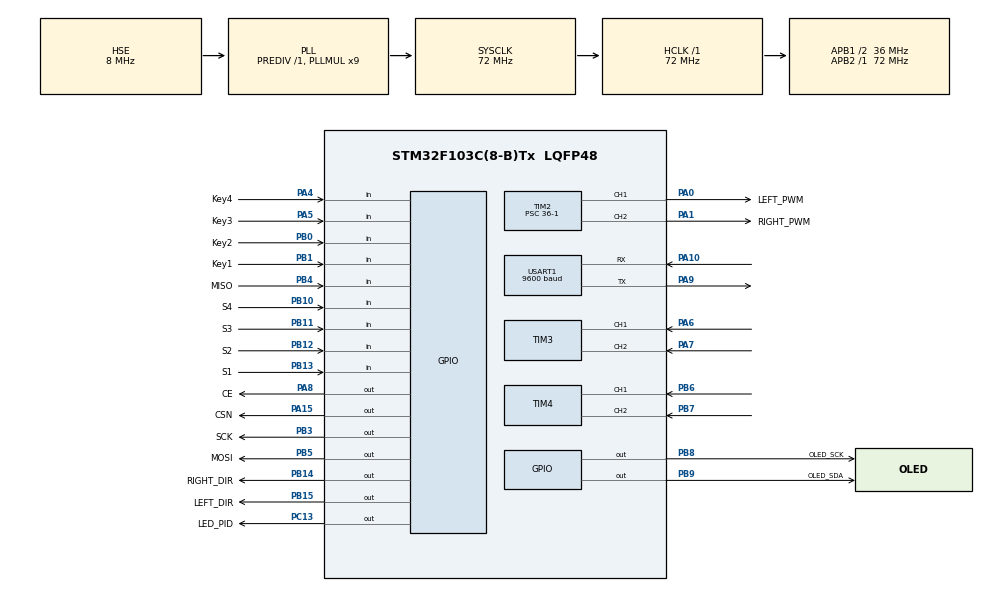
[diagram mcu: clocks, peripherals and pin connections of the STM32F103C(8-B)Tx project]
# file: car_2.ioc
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Dma.Request0=USART1_RX
Dma.USART1_RX.0.Direction=DMA_PERIPH_TO_MEMORY
Dma.USART1_RX.0.Instance=DMA1_Channel5
Dma.USART1_RX.0.MemDataAlignment=DMA_MDATAALIGN_BYTE
Dma.USART1_RX.0.MemInc=DMA_MINC_ENABLE
Dma.USART1_RX.0.Mode=DMA_NORMAL
Dma.USART1_RX.0.PeriphDataAlignment=DMA_PDATAALIGN_BYTE
Dma.USART1_RX.0.PeriphInc=DMA_PINC_DISABLE
Dma.USART1_RX.0.Priority=DMA_PRIORITY_LOW
Mcu.Family=STM32F1
Mcu.Name=STM32F103C(8-B)Tx
Mcu.Package=LQFP48
NVIC.DMA1_Channel5_IRQn=true\:0\:0\:false\:false\:true\:false\:true\:true
NVIC.PriorityGroup=NVIC_PRIORITYGROUP_4
NVIC.USART1_IRQn=true\:0\:0\:false\:false\:true\:true\:true\:true
PA0-WKUP.GPIO_Label=LEFT_PWM
PA0-WKUP.Signal=S_TIM2_CH1_ETR
PA1.GPIO_Label=RIGHT_PWM
PA1.Signal=S_TIM2_CH2
PA10.Mode=Asynchronous
PA10.Signal=USART1_RX
PA13.Mode=Serial_Wire
PA13.Signal=SYS_JTMS-SWDIO
PA14.Mode=Serial_Wire
PA14.Signal=SYS_JTCK-SWCLK
PA15.GPIO_Label=CSN
PA15.Signal=GPIO_Output
PA4.GPIO_Label=Key4
PA4.GPIO_PuPd=GPIO_PULLUP
PA4.Signal=GPIO_Input
PA5.GPIO_Label=Key3
PA5.GPIO_PuPd=GPIO_PULLUP
PA5.Signal=GPIO_Input
PA6.Signal=S_TIM3_CH1
PA7.Signal=S_TIM3_CH2
PA8.GPIO_Label=CE
PA8.Signal=GPIO_Output
PA9.Mode=Asynchronous
PA9.Signal=USART1_TX
PB0.GPIO_Label=Key2
PB0.GPIO_PuPd=GPIO_PULLUP
PB0.Signal=GPIO_Input
PB1.GPIO_Label=Key1
PB1.GPIO_PuPd=GPIO_PULLUP
PB1.Signal=GPIO_Input
PB10.GPIO_Label=S4
PB10.Signal=GPIO_Input
PB11.GPIO_Label=S3
PB11.Signal=GPIO_Input
PB12.GPIO_Label=S2
PB12.Signal=GPIO_Input
PB13.GPIO_Label=S1
PB13.Signal=GPIO_Input
PB14.GPIO_Label=RIGHT_DIR
PB14.Signal=GPIO_Output
PB15.GPIO_Label=LEFT_DIR
PB15.Signal=GPIO_Output
PB3.GPIO_Label=SCK
PB3.Signal=GPIO_Output
PB4.GPIO_Label=MISO
PB4.GPIO_PuPd=GPIO_PULLUP
PB4.Signal=GPIO_Input
PB5.GPIO_Label=MOSI
PB5.Signal=GPIO_Output
PB6.Signal=S_TIM4_CH1
PB7.Signal=S_TIM4_CH2
PB8.GPIO_Label=OLED_SCK
PB8.Signal=GPIO_Output
PB9.GPIO_Label=OLED_SDA
PB9.Signal=GPIO_Output
PC13-TAMPER-RTC.GPIO_Label=LED_PID
PC13-TAMPER-RTC.PinState=GPIO_PIN_SET
PC13-TAMPER-RTC.Signal=GPIO_Output
PD0-OSC_IN.Mode=HSE-External-Oscillator
PD0-OSC_IN.Signal=RCC_OSC_IN
PD1-OSC_OUT.Mode=HSE-External-Oscillator
PD1-OSC_OUT.Signal=RCC_OSC_OUT
ProjectManager.HeapSize=0x200
ProjectManager.StackSize=0x400
ProjectManager.TargetToolchain=MDK-ARM V5.32
RCC.AHBFreq_Value=72000000
RCC.APB1CLKDivider=RCC_HCLK_DIV2
RCC.APB1Freq_Value=36000000
RCC.APB1TimFreq_Value=72000000
RCC.APB2Freq_Value=72000000
RCC.APB2TimFreq_Value=72000000
RCC.HCLKFreq_Value=72000000
RCC.PLLMUL=RCC_PLL_MUL9
RCC.PLLSourceVirtual=RCC_PLLSOURCE_HSE
RCC.RTCClockSelection=RCC_RTCCLKSOURCE_LSE
RCC.SYSCLKFreq_VALUE=72000000
RCC.SYSCLKSource=RCC_SYSCLKSOURCE_PLLCLK
RCC.USBFreq_Value=72000000
SH.S_TIM2_CH1_ETR.0=TIM2_CH1,PWM Generation1 CH1
SH.S_TIM2_CH2.0=TIM2_CH2,PWM Generation2 CH2
SH.S_TIM3_CH1.0=TIM3_CH1,Encoder_Interface
SH.S_TIM3_CH2.0=TIM3_CH2,Encoder_Interface
SH.S_TIM4_CH1.0=TIM4_CH1,Encoder_Interface
SH.S_TIM4_CH2.0=TIM4_CH2,Encoder_Interface
TIM1.Period=100-1
TIM1.Prescaler=720-1
TIM2.Channel-PWM\ Generation1\ CH1=TIM_CHANNEL_1
TIM2.Channel-PWM\ Generation2\ CH2=TIM_CHANNEL_2
TIM2.Period=5000-1
TIM2.Prescaler=36-1
TIM3.EncoderMode=TIM_ENCODERMODE_TI12
TIM3.IC1Filter=15
TIM3.IC1Polarity=TIM_ICPOLARITY_FALLING
TIM4.EncoderMode=TIM_ENCODERMODE_TI12
TIM4.IC1Polarity=TIM_ICPOLARITY_FALLING
TIM4.IC2Polarity=TIM_ICPOLARITY_FALLING
USART1.BaudRate=9600
USART1.VirtualMode=VM_ASYNC
VP_TIM1_VS_ClockSourceINT.Mode=Internal
board=custom

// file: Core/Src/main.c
/* USER CODE BEGIN Header */
/**
  ******************************************************************************
  * @file           : main.c
  * @brief          : Main program body
  ******************************************************************************
  * @attention
  *
  * Copyright (c) 2026 STMicroelectronics.
  * All rights reserved.
  *
  * This software is licensed under terms that can be found in the LICENSE file
  * in the root directory of this software component.
  * If no LICENSE file comes with this software, it is provided AS-IS.
  *
  ******************************************************************************
  */
/* USER CODE END Header */
#include "main.h"
#include "dma.h"
#include "tim.h"
#include "usart.h"
#include "gpio.h"

/* USER CODE BEGIN PTD */
extern osThreadId_t task_1msHandle;
/* USER CODE END PTD */

void SystemClock_Config(void);

int main(void)
{

  /* MCU Configuration--------------------------------------------------------*/

  /* Reset of all peripherals, Initializes the Flash interface and the Systick. */
  HAL_Init();

  /* Configure the system clock */
  SystemClock_Config();

  /* Initialize all configured peripherals */
  MX_GPIO_Init();
  MX_DMA_Init();
  MX_TIM2_Init();
  MX_TIM3_Init();
  MX_TIM4_Init();
  MX_USART1_UART_Init();
  MX_TIM1_Init();

  /* Infinite loop */
  while (1)
  {

  }
}

void SystemClock_Config(void)
{
  RCC_OscInitTypeDef RCC_OscInitStruct = {0};
  RCC_ClkInitTypeDef RCC_ClkInitStruct = {0};

  /** Initializes the RCC Oscillators according to the specified parameters
  * in the RCC_OscInitTypeDef structure.
  */
  RCC_OscInitStruct.OscillatorType = RCC_OSCILLATORTYPE_HSE;
  RCC_OscInitStruct.HSEState = RCC_HSE_ON;
  RCC_OscInitStruct.HSEPredivValue = RCC_HSE_PREDIV_DIV1;
  RCC_OscInitStruct.HSIState = RCC_HSI_ON;
  RCC_OscInitStruct.PLL.PLLState = RCC_PLL_ON;
  RCC_OscInitStruct.PLL.PLLSource = RCC_PLLSOURCE_HSE;
  RCC_OscInitStruct.PLL.PLLMUL = RCC_PLL_MUL9;
  if (HAL_RCC_OscConfig(&RCC_OscInitStruct) != HAL_OK)
  {
    Error_Handler();
  }

  /** Initializes the CPU, AHB and APB buses clocks
  */
  RCC_ClkInitStruct.ClockType = RCC_CLOCKTYPE_HCLK|RCC_CLOCKTYPE_SYSCLK
                              |RCC_CLOCKTYPE_PCLK1|RCC_CLOCKTYPE_PCLK2;
  RCC_ClkInitStruct.SYSCLKSource = RCC_SYSCLKSOURCE_PLLCLK;
  RCC_ClkInitStruct.AHBCLKDivider = RCC_SYSCLK_DIV1;
  RCC_ClkInitStruct.APB1CLKDivider = RCC_HCLK_DIV2;
  RCC_ClkInitStruct.APB2CLKDivider = RCC_HCLK_DIV1;

  if (HAL_RCC_ClockConfig(&RCC_ClkInitStruct, FLASH_LATENCY_2) != HAL_OK)
  {
    Error_Handler();
  }
}

void Error_Handler(void)
{
  __disable_irq();
  while (1)
  {
  }
}
